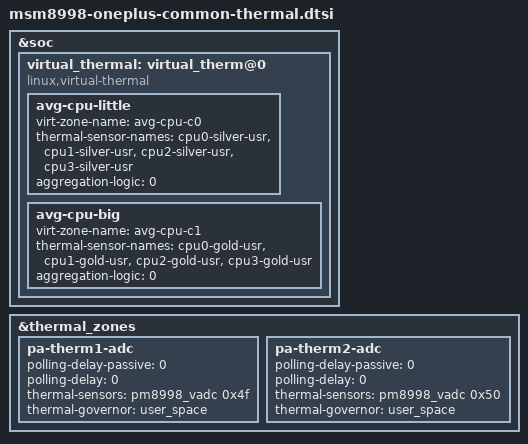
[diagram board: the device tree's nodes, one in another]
/* arch/arm64/boot/dts/qcom/msm8998-oneplus-common-thermal.dtsi
 *
 * This program is free software; you can redistribute it and/or modify
 * it under the terms of the GNU General Public License version 2 and
 * only version 2 as published by the Free Software Foundation.
 *
 * This program is distributed in the hope that it will be useful,
 * but WITHOUT ANY WARRANTY; without even the implied warranty of
 * MERCHANTABILITY or FITNESS FOR A PARTICULAR PURPOSE.  See the
 * GNU General Public License for more details.
 */
/*
 * Copyright (C) 2018 AngeloGioacchino Del Regno <kholk11@gmail.com>
 *
 * This program is free software; you can redistribute it and/or modify
 * it under the terms of the GNU General Public License version 2, as
 * published by the Free Software Foundation.
 */

&soc {
	virtual_thermal: virtual_therm@0 {
		compatible = "linux,virtual-thermal";
		status = "ok";
	};
};

&virtual_thermal {
	avg-cpu-little {
		virt-zone-name = "avg-cpu-c0";
		thermal-sensor-names = "cpu0-silver-usr", "cpu1-silver-usr",
				  "cpu2-silver-usr", "cpu3-silver-usr";
		aggregation-logic = <0>; /* WEIGHTED_AVG */
	};
	avg-cpu-big {
		virt-zone-name = "avg-cpu-c1";
		thermal-sensor-names = "cpu0-gold-usr", "cpu1-gold-usr",
				  "cpu2-gold-usr", "cpu3-gold-usr";
		aggregation-logic = <0>; /* WEIGHTED_AVG */
	};
};

&thermal_zones {
	pa-therm1-adc {
		polling-delay-passive = <0>;
		polling-delay = <0>;
		thermal-sensors = <&pm8998_vadc 0x4f>;
		thermal-governor = "user_space";
	};

	pa-therm2-adc {
		polling-delay-passive = <0>;
		polling-delay = <0>;
		thermal-sensors = <&pm8998_vadc 0x50>;
		thermal-governor = "user_space";
	};
};
